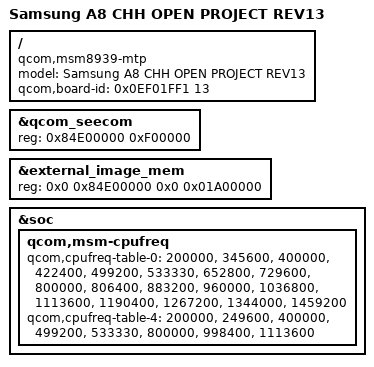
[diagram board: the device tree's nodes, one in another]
/*
 * Copyright (c) 2015, The Linux Foundation. All rights reserved.
 *
 * This program is free software; you can redistribute it and/or modify
 * it under the terms of the GNU General Public License version 2 and
 * only version 2 as published by the Free Software Foundation.
 *
 * This program is distributed in the hope that it will be useful,
 * but WITHOUT ANY WARRANTY; without even the implied warranty of
 * MERCHANTABILITY or FITNESS FOR A PARTICULAR PURPOSE.  See the
 * GNU General Public License for more details.
 */

/dts-v1/;

#include "msm8939-v3.0.dtsi"
#include "msm8939-audio-internal_codec.dtsi"
#include "msm8939-sec-a8-chn-r13.dtsi"

/ {
	model = "Samsung A8 CHH OPEN PROJECT REV13";
	compatible = "qcom,msm8939-mtp", "qcom,msm8939", "qcom,mtp";
        /*QCOM BOARD REV TYPE...*/
        /*qcom,board-id = <8 1>;*/
        /*SEC BOARD REV TYPE...*/
        qcom,board-id = <0x0EF01FF1 13>; /*EXTEND_PLATFORM_ID*/
        /*parm1)[31:20]platform_id [19:12]qc_hw_id [11:4]national code [3:0] operator, param2)SEC hw-rev*/
};

&qcom_seecom {
	reg = <0x84E00000 0xF00000>;
};

&external_image_mem {
	reg = <0x0 0x84E00000 0x0 0x01A00000>;
};

&soc {
	qcom,msm-cpufreq {
		qcom,cpufreq-table-0 =
			<  200000 >,
			<  345600 >,
			<  400000 >,
			<  422400 >,
			<  499200 >,
			<  533330 >,
			<  652800 >,
			<  729600 >,
			<  800000 >,
			<  806400 >,
			<  883200 >,
			<  960000 >,
			< 1036800 >,
			< 1113600 >,
			< 1190400 >,
			< 1267200 >,
			< 1344000 >,
			< 1459200 >;
		qcom,cpufreq-table-4 =
			<  200000 >,
			<  249600 >,
			<  400000 >,
			<  499200 >,
			<  533330 >,
			<  800000 >,
			<  998400 >,
			< 1113600 >;
	};
};
